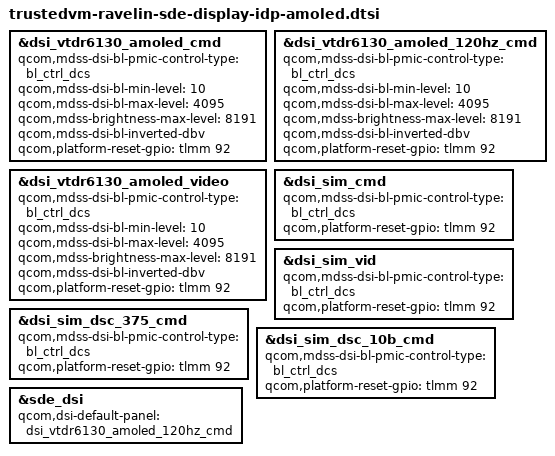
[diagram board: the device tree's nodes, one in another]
#include "trustedvm-ravelin-sde-display.dtsi"

&dsi_vtdr6130_amoled_cmd {
	qcom,mdss-dsi-bl-pmic-control-type = "bl_ctrl_dcs";
	qcom,mdss-dsi-bl-min-level = <10>;
	qcom,mdss-dsi-bl-max-level = <4095>;
	qcom,mdss-brightness-max-level = <8191>;
	qcom,mdss-dsi-bl-inverted-dbv;
	qcom,platform-reset-gpio = <&tlmm 92 0>;
};

&dsi_vtdr6130_amoled_120hz_cmd {
	qcom,mdss-dsi-bl-pmic-control-type = "bl_ctrl_dcs";
	qcom,mdss-dsi-bl-min-level = <10>;
	qcom,mdss-dsi-bl-max-level = <4095>;
	qcom,mdss-brightness-max-level = <8191>;
	qcom,mdss-dsi-bl-inverted-dbv;
	qcom,platform-reset-gpio = <&tlmm 92 0>;
};

&dsi_vtdr6130_amoled_video {
	qcom,mdss-dsi-bl-pmic-control-type = "bl_ctrl_dcs";
	qcom,mdss-dsi-bl-min-level = <10>;
	qcom,mdss-dsi-bl-max-level = <4095>;
	qcom,mdss-brightness-max-level = <8191>;
	qcom,mdss-dsi-bl-inverted-dbv;
	qcom,platform-reset-gpio = <&tlmm 92 0>;
};

&dsi_sim_cmd {
	qcom,mdss-dsi-bl-pmic-control-type = "bl_ctrl_dcs";
	qcom,platform-reset-gpio = <&tlmm 92 0>;
};

&dsi_sim_vid {
	qcom,mdss-dsi-bl-pmic-control-type = "bl_ctrl_dcs";
	qcom,platform-reset-gpio = <&tlmm 92 0>;
};

&dsi_sim_dsc_375_cmd {
	qcom,mdss-dsi-bl-pmic-control-type = "bl_ctrl_dcs";
	qcom,platform-reset-gpio = <&tlmm 92 0>;
};

&dsi_sim_dsc_10b_cmd {
	qcom,mdss-dsi-bl-pmic-control-type = "bl_ctrl_dcs";
	qcom,platform-reset-gpio = <&tlmm 92 0>;
};

&sde_dsi {
	qcom,dsi-default-panel = <&dsi_vtdr6130_amoled_120hz_cmd>;
};
